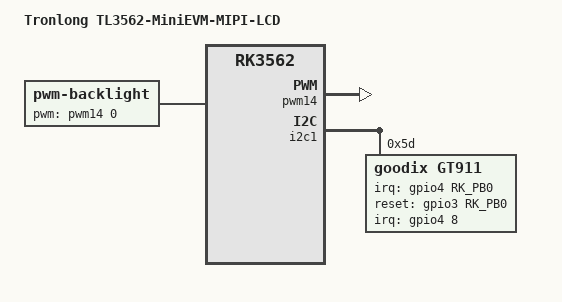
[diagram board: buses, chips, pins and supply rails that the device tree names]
/dts-v1/;

#include "rk3562-tl3562-minievm.dts"

/ {
	model = "Tronlong TL3562-MiniEVM-MIPI-LCD";

	backlight: backlight {
		compatible = "pwm-backlight";
		pwms = <&pwm14 0 25000 0>;
		brightness-levels = <
			  0  20  20  21  21  22  22  23
			 23  24  24  25  25  26  26  27
			 27  28  28  29  29  30  30  31
			 31  32  32  33  33  34  34  35
			 35  36  36  37  37  38  38  39
			 40  41  42  43  44  45  46  47
			 48  49  50  51  52  53  54  55
			 56  57  58  59  60  61  62  63
			 64  65  66  67  68  69  70  71
			 72  73  74  75  76  77  78  79
			 80  81  82  83  84  85  86  87
			 88  89  90  91  92  93  94  95
			 96  97  98  99 100 101 102 103
			104 105 106 107 108 109 110 111
			112 113 114 115 116 117 118 119
			120 121 122 123 124 125 126 127
			128 129 130 131 132 133 134 135
			136 137 138 139 140 141 142 143
			144 145 146 147 148 149 150 151
			152 153 154 155 156 157 158 159
			160 161 162 163 164 165 166 167
			168 169 170 171 172 173 174 175
			176 177 178 179 180 181 182 183
			184 185 186 187 188 189 190 191
			192 193 194 195 196 197 198 199
			200 201 202 203 204 205 206 207
			208 209 210 211 212 213 214 215
			216 217 218 219 220 221 222 223
			224 225 226 227 228 229 230 231
			232 233 234 235 236 237 238 239
			240 241 242 243 244 245 246 247
			248 249 250 251 252 253 254 255
		>;
		default-brightness-level = <200>;
	};
};

&pwm14 {
	status = "okay";
};

&dsi_panel {
	status = "okay";
	/delete-property/ enable-gpios;
	/delete-property/ pinctrl-names;
	/delete-property/ pinctrl-0;

	reset-gpios = <&gpio0 RK_PA0 GPIO_ACTIVE_LOW>;

	backlight = <&backlight>;

	dsi,flags = <(MIPI_DSI_MODE_VIDEO | MIPI_DSI_MODE_VIDEO_BURST |
		MIPI_DSI_MODE_LPM | MIPI_DSI_MODE_NO_EOT_PACKET)>;

	panel-init-sequence = [
		05 1E 01 01
		23 00 02 EE 50
		23 00 02 EA 85
		23 00 02 EB 55
		23 00 02 20 00
		23 00 02 24 A0
		23 00 02 30 00
		23 00 02 35 00
		23 00 02 50 00
		23 00 02 56 83
		23 00 02 79 00
		23 00 02 7A 20
		23 00 02 7D 00
		23 00 02 90 20
		23 00 02 91 50
		23 00 02 93 F8
		23 00 02 95 74
		23 00 02 97 0A
		23 00 02 99 10
		23 00 02 EE 60
		23 00 02 21 00
		23 00 02 27 62
		23 00 02 29 8A
		23 00 02 2C F9
		23 00 02 30 01
		23 00 02 31 AF
		23 00 02 32 DA
		23 00 02 33 F3
		23 00 02 34 EF
		23 00 02 3A 24
		23 00 02 3B 00
		23 00 02 3C 24
		23 00 02 3D 11
		23 00 02 3E 93
		23 00 02 42 64
		23 00 02 43 64
		23 00 02 44 0B
		23 00 02 46 4E
		23 00 02 47 0F
		23 00 02 48 24
		23 00 02 49 2C
		23 00 02 4A 39
		23 00 02 4B 36
		23 00 02 4C 46
		23 00 02 4D 39
		23 00 02 4E 4B
		23 00 02 4F 2C
		23 00 02 50 29
		23 00 02 51 27
		23 00 02 52 0A
		23 00 02 53 1F
		23 00 02 54 19
		23 00 02 55 2C
		23 00 02 56 34
		23 00 02 57 43
		23 00 02 58 58
		23 00 02 59 7F
		23 00 02 5A 0F
		23 00 02 5B 24
		23 00 02 5C 2C
		23 00 02 5D 39
		23 00 02 5E 36
		23 00 02 5F 46
		23 00 02 60 39
		23 00 02 61 4B
		23 00 02 62 2C
		23 00 02 63 29
		23 00 02 64 27
		23 00 02 65 0A
		23 00 02 66 1F
		23 00 02 67 19
		23 00 02 68 2C
		23 00 02 69 34
		23 00 02 6A 43
		23 00 02 6B 58
		23 00 02 6C 7F
		23 00 02 86 20
		23 00 02 89 00
		23 00 02 8B 33
		23 00 02 8B 90
		23 00 02 8D 02
		23 00 02 91 44
		23 00 02 92 33
		23 00 02 93 9F
		23 00 02 9A 00
		23 00 02 9C 80
		23 00 02 EE 70
		23 00 02 00 03
		23 00 02 01 07
		23 00 02 02 00
		23 00 02 03 01
		23 00 02 04 08
		23 00 02 05 0C
		23 00 02 06 55
		23 00 02 07 01
		23 00 02 0C 05
		23 00 02 0D 05
		23 00 02 10 06
		23 00 02 11 09
		23 00 02 12 00
		23 00 02 13 01
		23 00 02 14 05
		23 00 02 15 00
		23 00 02 16 15
		23 00 02 17 0D
		23 00 02 18 08
		23 00 02 19 00
		23 00 02 29 05
		23 00 02 2A 05
		23 00 02 60 3C
		23 00 02 61 3C
		23 00 02 62 07
		23 00 02 63 05
		23 00 02 64 17
		23 00 02 65 15
		23 00 02 66 13
		23 00 02 67 11
		23 00 02 68 01
		23 00 02 69 03
		23 00 02 6A 3C
		23 00 02 6B 3C
		23 00 02 6C 3C
		23 00 02 6D 3C
		23 00 02 6E 3C
		23 00 02 6F 3C
		23 00 02 70 3C
		23 00 02 71 3C
		23 00 02 72 3C
		23 00 02 73 3C
		23 00 02 74 3C
		23 00 02 75 3C
		23 00 02 80 3C
		23 00 02 81 3C
		23 00 02 82 06
		23 00 02 83 04
		23 00 02 84 16
		23 00 02 85 14
		23 00 02 86 12
		23 00 02 87 10
		23 00 02 88 00
		23 00 02 89 02
		23 00 02 8A 3C
		23 00 02 8B 3C
		23 00 02 8C 3C
		23 00 02 8D 3C
		23 00 02 8E 3C
		23 00 02 8F 3C
		23 00 02 90 3C
		23 00 02 91 3C
		23 00 02 92 3C
		23 00 02 93 3C
		23 00 02 94 3C
		23 00 02 95 3C
		23 00 02 EA 00
		23 00 02 EB 00
		23 00 02 EE 00
		05 78 01 11
		05 1E 01 29
	];

	panel-exit-sequence = [
		05 00 01 28
		05 00 01 10
	];
};

&dsi_timing0 {
	clock-frequency = <72000000>;
	hactive = <800>;
	vactive = <1280>;
	hfront-porch = <98>;
	hsync-len = <20>;
	hback-porch = <22>;
	vfront-porch = <24>;
	vsync-len = <8>;
	vback-porch = <8>;
	hsync-active = <0>;
	vsync-active = <0>;
	de-active = <0>;
	pixelclk-active = <1>;
};

&i2c1 {
	gt911@5d {
		status = "okay";
		compatible = "goodix,gt911";
		reg = <0x5d>;
		pinctrl-names = "default";
		pinctrl-0 = <&gt911_int>;
		interrupt-parent = <&gpio4>;
		interrupts = <8 0>;
		irq-gpios = <&gpio4 RK_PB0 0>;
		reset-gpios = <&gpio3 RK_PB0 0>;
	};
};

&pinctrl {
	mipi_panel {
		gt911_int: gt911-int {
			rockchip,pins = <4 RK_PB0 RK_FUNC_GPIO &pcfg_pull_none>;
		};
	};
};
